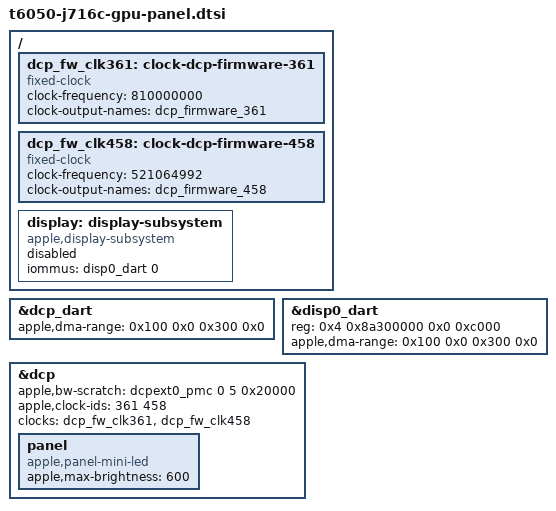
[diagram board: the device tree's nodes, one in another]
// SPDX-License-Identifier: GPL-2.0+ OR MIT
/*
 * J716c GPU and internal panel. The loader validates the running hardware,
 * fills the memory reservations and operating points, then enables the
 * dependent devices. A source DT alone must not start either coprocessor.
 */

/* The GPU: t6050-gpu-g17c.dtsi, shared with the other M5 Max boards. */
#include "t6050-gpu-g17c.dtsi"

/ {
	/* The loader verifies these clock identifiers and fills their rates. */
	dcp_fw_clk361: clock-dcp-firmware-361 {
		compatible = "fixed-clock";
		#clock-cells = <0>;
		clock-frequency = <810000000>;
		clock-output-names = "dcp_firmware_361";
	};

	dcp_fw_clk458: clock-dcp-firmware-458 {
		compatible = "fixed-clock";
		#clock-cells = <0>;
		clock-frequency = <521064992>;
		clock-output-names = "dcp_firmware_458";
	};

	display: display-subsystem {
		compatible = "apple,display-subsystem";
		iommus = <&disp0_dart 0>;
		status = "disabled";
	};
};

&dcp_dart {
	apple,dma-range = <0x100 0x0 0x300 0x0>;
};

&disp0_dart {
	reg = <0x4 0x8a300000 0x0 0xc000>;
	apple,dma-range = <0x100 0x0 0x300 0x0>;
};

&dcp {
	apple,bw-scratch = <&dcpext0_pmc 0 5 0x20000>;
	apple,clock-ids = <361 458>;
	clocks = <&dcp_fw_clk361>, <&dcp_fw_clk458>;
	clock-names = "firmware-0", "firmware-1";

	panel {
		compatible = "apple,panel-mini-led";
		apple,max-brightness = <600>;
	};
};
